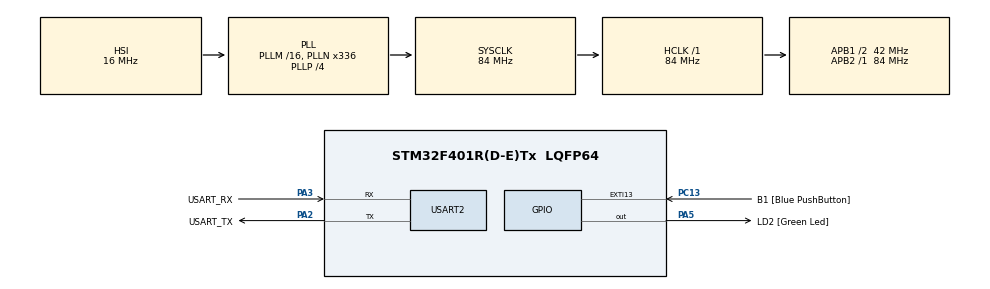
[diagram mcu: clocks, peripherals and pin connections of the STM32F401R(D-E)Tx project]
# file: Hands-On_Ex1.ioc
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FREERTOS.Tasks01=Task1,0,128,vTask1,Default,NULL,Dynamic,NULL,NULL;Task2,0,128,vTask2,Default,NULL,Dynamic,NULL,NULL
FREERTOS.configTICK_RATE_HZ=1000
Mcu.Family=STM32F4
Mcu.Name=STM32F401R(D-E)Tx
Mcu.Package=LQFP64
NVIC.PriorityGroup=NVIC_PRIORITYGROUP_4
NVIC.TIM1_TRG_COM_TIM11_IRQn=true\:0\:0\:false\:false\:true\:false\:false\:true
NVIC.TimeBase=TIM1_TRG_COM_TIM11_IRQn
NVIC.TimeBaseIP=TIM11
PA13.GPIO_Label=TMS
PA13.Mode=Serial_Wire
PA13.Signal=SYS_JTMS-SWDIO
PA14.GPIO_Label=TCK
PA14.Mode=Serial_Wire
PA14.Signal=SYS_JTCK-SWCLK
PA2.GPIO_Label=USART_TX
PA2.GPIO_Mode=GPIO_MODE_AF_PP
PA2.GPIO_PuPd=GPIO_NOPULL
PA2.GPIO_Speed=GPIO_SPEED_FREQ_LOW
PA2.Mode=Asynchronous
PA2.Signal=USART2_TX
PA3.GPIO_Label=USART_RX
PA3.GPIO_Mode=GPIO_MODE_AF_PP
PA3.GPIO_PuPd=GPIO_NOPULL
PA3.GPIO_Speed=GPIO_SPEED_FREQ_LOW
PA3.Mode=Asynchronous
PA3.Signal=USART2_RX
PA5.GPIO_Label=LD2 [Green Led]
PA5.GPIO_Mode=GPIO_MODE_OUTPUT_PP
PA5.GPIO_PuPd=GPIO_NOPULL
PA5.GPIO_Speed=GPIO_SPEED_FREQ_LOW
PA5.Signal=GPIO_Output
PB3.GPIO_Label=SWO
PB3.Signal=SYS_JTDO-SWO
PC13-ANTI_TAMP.GPIO_Label=B1 [Blue PushButton]
PC13-ANTI_TAMP.GPIO_ModeDefaultEXTI=GPIO_MODE_IT_FALLING
PC13-ANTI_TAMP.GPIO_PuPd=GPIO_NOPULL
PC13-ANTI_TAMP.Signal=GPXTI13
PC14-OSC32_IN.Mode=LSE-External-Oscillator
PC14-OSC32_IN.Signal=RCC_OSC32_IN
PC15-OSC32_OUT.Mode=LSE-External-Oscillator
PC15-OSC32_OUT.Signal=RCC_OSC32_OUT
PH0\ -\ OSC_IN.Mode=HSE-External-Clock-Source
PH0\ -\ OSC_IN.Signal=RCC_OSC_IN
PH1\ -\ OSC_OUT.Mode=HSE-External-Clock-Source
PH1\ -\ OSC_OUT.Signal=RCC_OSC_OUT
ProjectManager.HeapSize=0x200
ProjectManager.StackSize=0x400
ProjectManager.TargetToolchain=TrueSTUDIO
RCC.48MHZClocksFreq_Value=48000000
RCC.AHBFreq_Value=84000000
RCC.APB1CLKDivider=RCC_HCLK_DIV2
RCC.APB1Freq_Value=42000000
RCC.APB1TimFreq_Value=84000000
RCC.APB2Freq_Value=84000000
RCC.APB2TimFreq_Value=84000000
RCC.CortexFreq_Value=84000000
RCC.HCLKFreq_Value=84000000
RCC.HSE_VALUE=8000000
RCC.HSI_VALUE=16000000
RCC.PLLN=336
RCC.PLLP=RCC_PLLP_DIV4
RCC.PLLQ=7
RCC.SYSCLKFreq_VALUE=84000000
RCC.SYSCLKSource=RCC_SYSCLKSOURCE_PLLCLK
RCC.VCOOutputFreq_Value=336000000
USART2.VirtualMode=VM_ASYNC
VP_FREERTOS_VS_CMSIS_V1.Mode=CMSIS_V1
VP_SYS_VS_tim11.Mode=TIM11
board=NUCLEO-F401RE

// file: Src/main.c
/* USER CODE BEGIN Header */
/**
  ******************************************************************************
  * @file           : main.c
  * @brief          : Main program body
  ******************************************************************************
  * @attention
  *
  * <h2><center>&copy; Copyright (c) 2019 STMicroelectronics.
  * All rights reserved.</center></h2>
  *
  * This software component is licensed by ST under Ultimate Liberty license
  * SLA0044, the "License"; You may not use this file except in compliance with
  * the License. You may obtain a copy of the License at:
  *                             www.st.com/SLA0044
  *
  ******************************************************************************
  */
/* USER CODE END Header */

#include "main.h"
#include "cmsis_os.h"
#include "usart.h"
#include "gpio.h"

void SystemClock_Config(void);
void MX_FREERTOS_Init(void);

int main(void)
{

  /* MCU Configuration--------------------------------------------------------*/

  /* Reset of all peripherals, Initializes the Flash interface and the Systick. */
  HAL_Init();

  /* Configure the system clock */
  SystemClock_Config();

  /* Initialize all configured peripherals */
  MX_GPIO_Init();
  MX_USART2_UART_Init();

  /* Call init function for freertos objects (in freertos.c) */
  MX_FREERTOS_Init();

  /* Start scheduler */
  osKernelStart();

  /* We should never get here as control is now taken by the scheduler */

  /* Infinite loop */
  while (1)
  {

  }
}

void SystemClock_Config(void)
{
  RCC_OscInitTypeDef RCC_OscInitStruct = {0};
  RCC_ClkInitTypeDef RCC_ClkInitStruct = {0};

  /** Configure the main internal regulator output voltage
  */
  __HAL_RCC_PWR_CLK_ENABLE();
  __HAL_PWR_VOLTAGESCALING_CONFIG(PWR_REGULATOR_VOLTAGE_SCALE2);
  /** Initializes the CPU, AHB and APB busses clocks
  */
  RCC_OscInitStruct.OscillatorType = RCC_OSCILLATORTYPE_HSI;
  RCC_OscInitStruct.HSIState = RCC_HSI_ON;
  RCC_OscInitStruct.HSICalibrationValue = RCC_HSICALIBRATION_DEFAULT;
  RCC_OscInitStruct.PLL.PLLState = RCC_PLL_ON;
  RCC_OscInitStruct.PLL.PLLSource = RCC_PLLSOURCE_HSI;
  RCC_OscInitStruct.PLL.PLLM = 16;
  RCC_OscInitStruct.PLL.PLLN = 336;
  RCC_OscInitStruct.PLL.PLLP = RCC_PLLP_DIV4;
  RCC_OscInitStruct.PLL.PLLQ = 7;
  if (HAL_RCC_OscConfig(&RCC_OscInitStruct) != HAL_OK)
  {
    Error_Handler();
  }
  /** Initializes the CPU, AHB and APB busses clocks
  */
  RCC_ClkInitStruct.ClockType = RCC_CLOCKTYPE_HCLK|RCC_CLOCKTYPE_SYSCLK
                              |RCC_CLOCKTYPE_PCLK1|RCC_CLOCKTYPE_PCLK2;
  RCC_ClkInitStruct.SYSCLKSource = RCC_SYSCLKSOURCE_PLLCLK;
  RCC_ClkInitStruct.AHBCLKDivider = RCC_SYSCLK_DIV1;
  RCC_ClkInitStruct.APB1CLKDivider = RCC_HCLK_DIV2;
  RCC_ClkInitStruct.APB2CLKDivider = RCC_HCLK_DIV1;

  if (HAL_RCC_ClockConfig(&RCC_ClkInitStruct, FLASH_LATENCY_2) != HAL_OK)
  {
    Error_Handler();
  }
}

void HAL_TIM_PeriodElapsedCallback(TIM_HandleTypeDef *htim)
{
  if (htim->Instance == TIM11) {
    HAL_IncTick();
  }
}

void Error_Handler(void)
{
}

/************************ (C) COPYRIGHT STMicroelectronics *****END OF FILE****/

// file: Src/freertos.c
/* USER CODE BEGIN Header */
/**
 ******************************************************************************
 * File Name          : freertos.c
 * Description        : Code for freertos applications
 ******************************************************************************
 * @attention
 *
 * <h2><center>&copy; Copyright (c) 2019 STMicroelectronics.
 * All rights reserved.</center></h2>
 *
 * This software component is licensed by ST under Ultimate Liberty license
 * SLA0044, the "License"; You may not use this file except in compliance with
 * the License. You may obtain a copy of the License at:
 *                             www.st.com/SLA0044
 *
 ******************************************************************************
 */
/* USER CODE END Header */

#include "FreeRTOS.h"
#include "task.h"
#include "main.h"
#include "cmsis_os.h"

/* USER CODE BEGIN Includes */

#include <string.h>
#include "usart.h"

/* USER CODE END Includes */

osThreadId Task1Handle;
osThreadId Task2Handle;

void vTask1(void const * argument);
void vTask2(void const * argument);

void MX_FREERTOS_Init(void); /* (MISRA C 2004 rule 8.1) */

void MX_FREERTOS_Init(void) {

  /* Create the thread(s) */
  /* definition and creation of Task1 */
  osThreadDef(Task1, vTask1, osPriorityNormal, 0, 128);
  Task1Handle = osThreadCreate(osThread(Task1), NULL);

  /* definition and creation of Task2 */
  osThreadDef(Task2, vTask2, osPriorityNormal, 0, 128);
  Task2Handle = osThreadCreate(osThread(Task2), NULL);

}

void vTask1(void const * argument)
{

  /* USER CODE BEGIN vTask1 */
	const char *pcTaskName = "Task 1 is running\r\n";

	/* Infinite loop */
	for(;;)
	{
		HAL_UART_Transmit(&huart2, (uint8_t *)pcTaskName, (uint16_t)strlen(pcTaskName), HAL_MAX_DELAY);
		osDelay(100);
	}
	osThreadTerminate(NULL);
  /* USER CODE END vTask1 */
}

void vTask2(void const * argument)
{
  /* USER CODE BEGIN vTask2 */
	const char *pcTaskName = "Task 2 is running\r\n";

	/* Infinite loop */
	for(;;)
	{
		HAL_UART_Transmit(&huart2, (uint8_t *)pcTaskName, (uint16_t)strlen(pcTaskName), HAL_MAX_DELAY);
		osDelay(100);
	}
	osThreadTerminate(NULL);
  /* USER CODE END vTask2 */
}

/************************ (C) COPYRIGHT STMicroelectronics *****END OF FILE****/
